# STM32L562 register map
File version: 1.1
Registers are 32-bit, read-write, reset 0x0 unless marked. A register's access mark holds for its fields unless they carry their own. Offsets are from the block's base; [hi:lo] are bit positions; 'fields as' and 'values as' point back to an identical list.

## SPI1 — Serial peripheral interface
Base 0x40013000
Same registers: SPI2 0x40003800, SPI3 0x40003C00, SEC_SPI2 0x50003800, SEC_SPI3 0x50003C00, SEC_SPI1 0x50013000
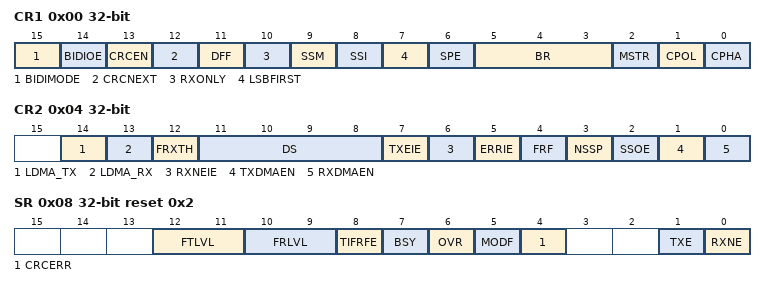
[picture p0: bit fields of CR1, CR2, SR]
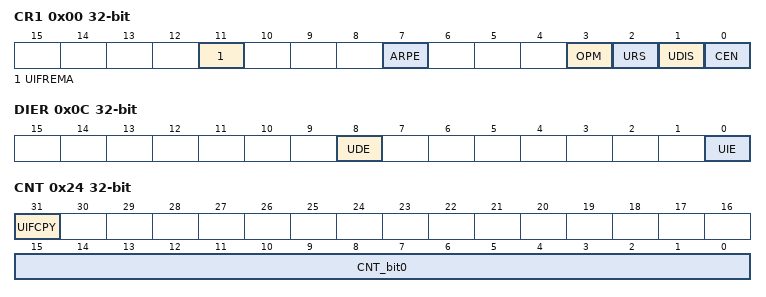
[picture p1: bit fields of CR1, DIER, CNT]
0x00 CR1 — control register 1
  [15] BIDIMODE — Bidirectional data mode enable
  [14] BIDIOE — Output enable in bidirectional mode
  [13] CRCEN — Hardware CRC calculation enable
  [12] CRCNEXT — CRC transfer next
  [11] DFF — Data frame format
  [10] RXONLY — Receive only
  [9] SSM — Software slave management
  [8] SSI — Internal slave select
  [7] LSBFIRST — Frame format
  [6] SPE — SPI enable
  [5:3] BR — Baud rate control
  [2] MSTR — Master selection
  [1] CPOL — Clock polarity
  [0] CPHA — Clock phase
0x04 CR2 — control register 2
  [14] LDMA_TX — Last DMA transfer for transmission
  [13] LDMA_RX — Last DMA transfer for reception
  [12] FRXTH — FIFO reception threshold
  [11:8] DS — Data size
  [7] TXEIE — Tx buffer empty interrupt enable
  [6] RXNEIE — RX buffer not empty interrupt enable
  [5] ERRIE — Error interrupt enable
  [4] FRF — Frame format
  [3] NSSP — NSS pulse management
  [2] SSOE — SS output enable
  [1] TXDMAEN — Tx buffer DMA enable
  [0] RXDMAEN — Rx buffer DMA enable
0x08 SR access per field reset 0x2 — status register
  [12:11] FTLVL ro — FIFO transmission level
  [10:9] FRLVL ro — FIFO reception level
  [8] TIFRFE ro — TI frame format error
  [7] BSY ro — Busy flag
  [6] OVR ro — Overrun flag
  [5] MODF ro — Mode fault
  [4] CRCERR rw — CRC error flag
  [1] TXE ro — Transmit buffer empty
  [0] RXNE ro — Receive buffer not empty
0x0C DR — data register
  [15:0] DR — Data register
0x10 CRCPR reset 0x7 — CRC polynomial register
  [15:0] CRCPOLY
0x14 RXCRCR ro — RX CRC register
  [15:0] RxCRC
0x18 TXCRCR ro — TX CRC register
  [15:0] TxCRC

## TIM6 — General-purpose-timers
Base 0x40001000
Same registers: TIM7 0x40001400, SEC_TIM6 0x50001000, SEC_TIM7 0x50001400
0x00 CR1 — control register 1
  [11] UIFREMA — UIF status bit remapping
  [7] ARPE — Auto-reload preload enable
  [3] OPM — One-pulse mode
  [2] URS — Update request source
  [1] UDIS — Update disable
  [0] CEN — Counter enable
0x04 CR2 — control register 2
  [6:4] MMS — Master mode selection
0x0C DIER — DMA/Interrupt enable register
  [8] UDE — Update DMA request enable
  [0] UIE — Update interrupt enable
0x10 SR — status register
  [0] UIF — Update interrupt flag
0x14 EGR wo — event generation register
  [0] UG — Update generation
0x24 CNT — counter
  [31] UIFCPY — UIFCPY or Res
  [15:0] CNT_bit0 — CNT
0x28 PSC — prescaler
  [15:0] PSC — Prescaler value
0x2C ARR reset 0xFFFFFFFF — auto-reload register
  [15:0] ARR_bit0

## OPAMP — Operational amplifiers
Base 0x40007800
Same registers: SEC_OPAMP 0x50007800
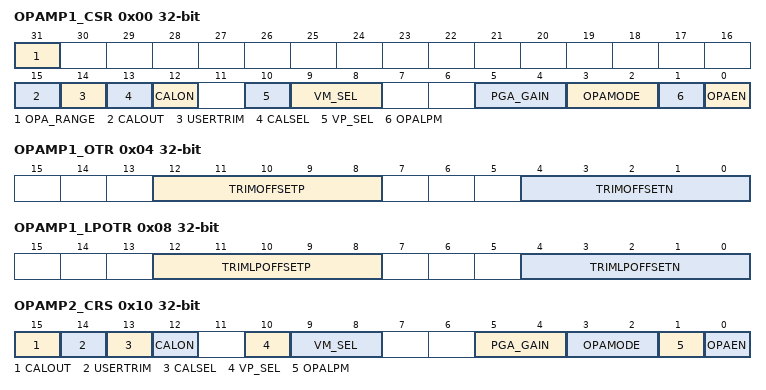
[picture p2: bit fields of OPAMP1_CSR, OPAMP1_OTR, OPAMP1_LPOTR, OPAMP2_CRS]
0x00 OPAMP1_CSR — OPAMP1 control/status register
  [31] OPA_RANGE — Operational amplifier power supply range for stability
  [15] CALOUT — Operational amplifier calibration output
  [14] USERTRIM — User trimming enable
  [13] CALSEL — calibration selection
  [12] CALON — calibration mode enable
  [10] VP_SEL — non inverted input selection
  [9:8] VM_SEL — inverting input selection
  [5:4] PGA_GAIN — Operational amplifier Programmable amplifier gain value
  [3:2] OPAMODE — Operational amplifier PGA mode
  [1] OPALPM — Operational amplifier Low Power Mode
  [0] OPAEN — Operational amplifier Enable
0x04 OPAMP1_OTR — OPAMP1 offset trimming register in normal mode
  [12:8] TRIMOFFSETP — Trim for PMOS differential pairs
  [4:0] TRIMOFFSETN — Trim for NMOS differential pairs
0x08 OPAMP1_LPOTR — OPAMP1 offset trimming register in low-powe mode
  [12:8] TRIMLPOFFSETP — Trim for PMOS differential pairs
  [4:0] TRIMLPOFFSETN — Trim for NMOS differential pairs
0x10 OPAMP2_CRS — OPAMP2 control/status register
  [15] CALOUT — Operational amplifier calibration output
  [14] USERTRIM — User trimming enable
  [13] CALSEL — calibration selection
  [12] CALON — calibration mode enable
  [10] VP_SEL — non inverted input selection
  [9:8] VM_SEL — inverting input selection
  [5:4] PGA_GAIN — Operational amplifier Programmable amplifier gain value
  [3:2] OPAMODE — Operational amplifier PGA mode
  [1] OPALPM — Operational amplifier Low Power Mode
  [0] OPAEN — Operational amplifier Enable
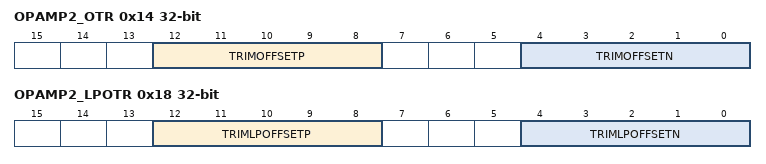
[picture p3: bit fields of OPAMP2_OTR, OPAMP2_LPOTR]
0x14 OPAMP2_OTR — OPAMP2 offset trimming register in normal mode
  fields as OPAMP1_OTR
0x18 OPAMP2_LPOTR — OPAMP2 offset trimming register in low-power mode
  fields as OPAMP1_LPOTR
